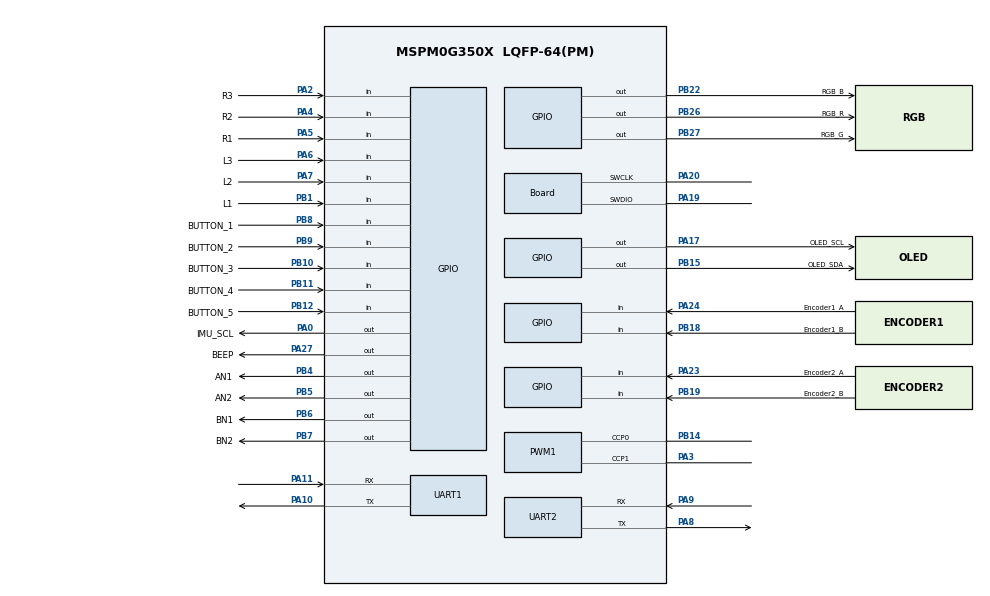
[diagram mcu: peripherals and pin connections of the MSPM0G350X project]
/**
 * @cliArgs --device "MSPM0G350X" --package "LQFP-64(PM)" --part "Default" --product "mspm0_sdk@2.00.01.00"
 * @versions {"tool":"1.20.0+3587"}
 */

/**
 * Import the modules used in this configuration.
 */
const ADC12         = scripting.addModule("/ti/driverlib/ADC12", {}, false);
const ADC121        = ADC12.addInstance();
const GPIO          = scripting.addModule("/ti/driverlib/GPIO", {}, false);
const GPIO1         = GPIO.addInstance();
const GPIO2         = GPIO.addInstance();
const GPIO3         = GPIO.addInstance();
const GPIO4         = GPIO.addInstance();
const PWM           = scripting.addModule("/ti/driverlib/PWM", {}, false);
const PWM1          = PWM.addInstance();
const SPI           = scripting.addModule("/ti/driverlib/SPI", {}, false);
const SPI1          = SPI.addInstance();
const SYSCTL        = scripting.addModule("/ti/driverlib/SYSCTL");
const SYSTICK       = scripting.addModule("/ti/driverlib/SYSTICK");
const TIMER         = scripting.addModule("/ti/driverlib/TIMER", {}, false);
const TIMER1        = TIMER.addInstance();
const TIMER2        = TIMER.addInstance();
const UART          = scripting.addModule("/ti/driverlib/UART", {}, false);
const UART1         = UART.addInstance();
const UART2         = UART.addInstance();
const ProjectConfig = scripting.addModule("/ti/project_config/ProjectConfig");

/**
 * Write custom configuration values to the imported modules.
 */
const divider2       = system.clockTree["HFCLK4MFPCLKDIV"];
divider2.divideValue = 10;

const divider6       = system.clockTree["PLL_CLK2X_DIV"];
divider6.divideValue = 4;

const divider7       = system.clockTree["PLL_PDIV"];
divider7.divideValue = 2;

const divider9       = system.clockTree["UDIV"];
divider9.divideValue = 2;

const multiplier2         = system.clockTree["PLL_QDIV"];
multiplier2.multiplyValue = 10;

const mux8       = system.clockTree["HSCLKMUX"];
mux8.inputSelect = "HSCLKMUX_SYSPLL2X";

const pinFunction4        = system.clockTree["HFXT"];
pinFunction4.inputFreq    = 40;
pinFunction4.HFXTStartup  = 20;
pinFunction4.HFCLKMonitor = true;

ADC121.$name               = "ADC12_0";
ADC121.sampClkSrc          = "DL_ADC12_CLOCK_ULPCLK";
ADC121.sampClkDiv          = "DL_ADC12_CLOCK_DIVIDE_8";
ADC121.powerDownMode       = "DL_ADC12_POWER_DOWN_MODE_MANUAL";
ADC121.sampleTime0         = "125us";
ADC121.adcMem0chansel      = "DL_ADC12_INPUT_CHAN_2";
ADC121.enabledInterrupts   = ["DL_ADC12_INTERRUPT_MEM0_RESULT_LOADED"];
ADC121.interruptPriority   = "3";
ADC121.adcPin2Config.$name = "ti_driverlib_gpio_GPIOPinGeneric6";

const Board                       = scripting.addModule("/ti/driverlib/Board", {}, false);
Board.peripheral.$assign          = "DEBUGSS";
Board.peripheral.swclkPin.$assign = "PA20";
Board.peripheral.swdioPin.$assign = "PA19";

GPIO1.$name                               = "PORTA";
GPIO1.port                                = "PORTA";
GPIO1.associatedPins.create(9);
GPIO1.associatedPins[0].$name             = "OLED_SCL";
GPIO1.associatedPins[0].internalResistor  = "PULL_UP";
GPIO1.associatedPins[0].pin.$assign       = "PA17";
GPIO1.associatedPins[1].$name             = "Encoder1_A";
GPIO1.associatedPins[1].direction         = "INPUT";
GPIO1.associatedPins[1].interruptEn       = true;
GPIO1.associatedPins[1].interruptPriority = "1";
GPIO1.associatedPins[1].polarity          = "RISE";
GPIO1.associatedPins[1].pin.$assign       = "PA24";
GPIO1.associatedPins[2].direction         = "INPUT";
GPIO1.associatedPins[2].$name             = "Encoder2_A";
GPIO1.associatedPins[2].interruptEn       = true;
GPIO1.associatedPins[2].interruptPriority = "1";
GPIO1.associatedPins[2].polarity          = "RISE";
GPIO1.associatedPins[2].pin.$assign       = "PA23";
GPIO1.associatedPins[3].$name             = "R2";
GPIO1.associatedPins[3].direction         = "INPUT";
GPIO1.associatedPins[3].pin.$assign       = "PA4";
GPIO1.associatedPins[4].$name             = "R3";
GPIO1.associatedPins[4].direction         = "INPUT";
GPIO1.associatedPins[4].pin.$assign       = "PA2";
GPIO1.associatedPins[5].$name             = "BEEP";
GPIO1.associatedPins[5].pin.$assign       = "PA27";
GPIO1.associatedPins[6].$name             = "L2";
GPIO1.associatedPins[6].direction         = "INPUT";
GPIO1.associatedPins[6].pin.$assign       = "PA7";
GPIO1.associatedPins[7].$name             = "L3";
GPIO1.associatedPins[7].direction         = "INPUT";
GPIO1.associatedPins[7].pin.$assign       = "PA6";
GPIO1.associatedPins[8].$name             = "R1";
GPIO1.associatedPins[8].direction         = "INPUT";
GPIO1.associatedPins[8].pin.$assign       = "PA5";

GPIO2.$name                               = "PORTB";
GPIO2.port                                = "PORTB";
GPIO2.associatedPins.create(11);
GPIO2.associatedPins[0].$name             = "RGB_R";
GPIO2.associatedPins[0].pin.$assign       = "PB26";
GPIO2.associatedPins[1].$name             = "RGB_G";
GPIO2.associatedPins[1].pin.$assign       = "PB27";
GPIO2.associatedPins[2].$name             = "RGB_B";
GPIO2.associatedPins[2].pin.$assign       = "PB22";
GPIO2.associatedPins[3].$name             = "OLED_SDA";
GPIO2.associatedPins[3].internalResistor  = "PULL_UP";
GPIO2.associatedPins[3].pin.$assign       = "PB15";
GPIO2.associatedPins[4].direction         = "INPUT";
GPIO2.associatedPins[4].interruptPriority = "1";
GPIO2.associatedPins[4].polarity          = "RISE";
GPIO2.associatedPins[4].$name             = "Encoder1_B";
GPIO2.associatedPins[4].pin.$assign       = "PB18";
GPIO2.associatedPins[5].$name             = "Encoder2_B";
GPIO2.associatedPins[5].direction         = "INPUT";
GPIO2.associatedPins[5].pin.$assign       = "PB19";
GPIO2.associatedPins[6].$name             = "AN1";
GPIO2.associatedPins[6].pin.$assign       = "PB4";
GPIO2.associatedPins[7].$name             = "AN2";
GPIO2.associatedPins[7].pin.$assign       = "PB5";
GPIO2.associatedPins[8].$name             = "BN1";
GPIO2.associatedPins[8].pin.$assign       = "PB6";
GPIO2.associatedPins[9].$name             = "BN2";
GPIO2.associatedPins[9].pin.$assign       = "PB7";
GPIO2.associatedPins[10].$name            = "L1";
GPIO2.associatedPins[10].direction        = "INPUT";
GPIO2.associatedPins[10].internalResistor = "PULL_UP";
GPIO2.associatedPins[10].pin.$assign      = "PB1";

GPIO3.port                               = "PORTB";
GPIO3.$name                              = "KEY";
GPIO3.associatedPins.create(5);
GPIO3.associatedPins[0].$name            = "BUTTON_1";
GPIO3.associatedPins[0].direction        = "INPUT";
GPIO3.associatedPins[0].internalResistor = "PULL_UP";
GPIO3.associatedPins[0].pin.$assign      = "PB8";
GPIO3.associatedPins[1].$name            = "BUTTON_2";
GPIO3.associatedPins[1].direction        = "INPUT";
GPIO3.associatedPins[1].internalResistor = "PULL_UP";
GPIO3.associatedPins[1].pin.$assign      = "PB9";
GPIO3.associatedPins[2].$name            = "BUTTON_3";
GPIO3.associatedPins[2].direction        = "INPUT";
GPIO3.associatedPins[2].internalResistor = "PULL_UP";
GPIO3.associatedPins[2].pin.$assign      = "PB10";
GPIO3.associatedPins[3].$name            = "BUTTON_4";
GPIO3.associatedPins[3].direction        = "INPUT";
GPIO3.associatedPins[3].internalResistor = "PULL_UP";
GPIO3.associatedPins[3].pin.$assign      = "PB11";
GPIO3.associatedPins[4].$name            = "BUTTON_5";
GPIO3.associatedPins[4].direction        = "INPUT";
GPIO3.associatedPins[4].internalResistor = "PULL_UP";
GPIO3.associatedPins[4].pin.$assign      = "PB12";

GPIO4.$name                          = "IMU";
GPIO4.port                           = "PORTA";
GPIO4.associatedPins.create(2);
GPIO4.associatedPins[0].$name        = "IMU_SDA";
GPIO4.associatedPins[0].ioStructure  = "OD";
GPIO4.associatedPins[0].initialValue = "SET";
GPIO4.associatedPins[1].$name        = "IMU_SCL";
GPIO4.associatedPins[1].ioStructure  = "OD";
GPIO4.associatedPins[1].initialValue = "SET";
GPIO4.associatedPins[1].pin.$assign  = "PA0";

PWM1.$name                      = "PWM_0";
PWM1.clockDivider               = 8;
PWM1.clockPrescale              = 10;
PWM1.pwmMode                    = "EDGE_ALIGN_UP";
PWM1.timerCount                 = 100;
PWM1.peripheral.ccp0Pin.$assign = "PB14";
PWM1.peripheral.ccp1Pin.$assign = "PA3";
PWM1.PWM_CHANNEL_0.$name        = "ti_driverlib_pwm_PWMTimerCC0";
PWM1.PWM_CHANNEL_1.$name        = "ti_driverlib_pwm_PWMTimerCC1";
PWM1.ccp0PinConfig.$name        = "ti_driverlib_gpio_GPIOPinGeneric4";
PWM1.ccp1PinConfig.$name        = "ti_driverlib_gpio_GPIOPinGeneric5";

SPI1.$name                              = "ICM_SPI_0";
SPI1.calculatedBitRate                  = -1;
SPI1.sclkPinConfig.direction            = scripting.forceWrite("OUTPUT");
SPI1.sclkPinConfig.onlyInternalResistor = scripting.forceWrite(false);
SPI1.sclkPinConfig.passedPeripheralType = scripting.forceWrite("Digital");
SPI1.sclkPinConfig.$name                = "ti_driverlib_gpio_GPIOPinGeneric9";
SPI1.mosiPinConfig.direction            = scripting.forceWrite("OUTPUT");
SPI1.mosiPinConfig.hideOutputInversion  = scripting.forceWrite(false);
SPI1.mosiPinConfig.onlyInternalResistor = scripting.forceWrite(false);
SPI1.mosiPinConfig.passedPeripheralType = scripting.forceWrite("Digital");
SPI1.mosiPinConfig.$name                = "ti_driverlib_gpio_GPIOPinGeneric10";
SPI1.misoPinConfig.onlyInternalResistor = scripting.forceWrite(false);
SPI1.misoPinConfig.passedPeripheralType = scripting.forceWrite("Digital");
SPI1.misoPinConfig.$name                = "ti_driverlib_gpio_GPIOPinGeneric11";
SPI1.cs0PinConfig.direction             = scripting.forceWrite("OUTPUT");
SPI1.cs0PinConfig.hideOutputInversion   = scripting.forceWrite(false);
SPI1.cs0PinConfig.onlyInternalResistor  = scripting.forceWrite(false);
SPI1.cs0PinConfig.passedPeripheralType  = scripting.forceWrite("Digital");
SPI1.cs0PinConfig.$name                 = "ti_driverlib_gpio_GPIOPinGeneric12";

SYSCTL.clockTreeEn = true;

SYSTICK.periodEnable      = true;
SYSTICK.period            = 80000;
SYSTICK.interruptEnable   = true;
SYSTICK.interruptPriority = "0";
SYSTICK.systickEnable     = true;

TIMER1.$name              = "TIMER_0";
TIMER1.timerMode          = "PERIODIC_UP";
TIMER1.interrupts         = ["ZERO"];
TIMER1.timerClkPrescale   = 5;
TIMER1.timerPeriod        = "5ms";
TIMER1.interruptPriority  = "2";
TIMER1.peripheral.$assign = "TIMG0";

TIMER2.timerClkDiv        = 8;
TIMER2.timerMode          = "PERIODIC_UP";
TIMER2.timerPeriod        = "1 ms";
TIMER2.interrupts         = ["ZERO"];
TIMER2.interruptPriority  = "1";
TIMER2.$name              = "TIMER_12";
TIMER2.peripheral.$assign = "TIMG12";

UART1.$name                    = "UART_0";
UART1.rxFifoThreshold          = "DL_UART_RX_FIFO_LEVEL_ONE_ENTRY";
UART1.enableDMARX              = false;
UART1.enableDMATX              = false;
UART1.enabledInterrupts        = ["RX"];
UART1.interruptPriority        = "1";
UART1.calculatedBaudRate       = -2;
UART1.peripheral.rxPin.$assign = "PA11";
UART1.peripheral.txPin.$assign = "PA10";
UART1.txPinConfig.$name        = "ti_driverlib_gpio_GPIOPinGeneric0";
UART1.rxPinConfig.$name        = "ti_driverlib_gpio_GPIOPinGeneric1";

UART2.$name                    = "UART_1";
UART2.enableFIFO               = true;
UART2.rxFifoThreshold          = "DL_UART_RX_FIFO_LEVEL_ONE_ENTRY";
UART2.enabledInterrupts        = ["RX"];
UART2.interruptPriority        = "1";
UART2.calculatedBaudRate       = -2;
UART2.peripheral.rxPin.$assign = "PA9";
UART2.peripheral.txPin.$assign = "PA8";
UART2.txPinConfig.$name        = "ti_driverlib_gpio_GPIOPinGeneric2";
UART2.rxPinConfig.$name        = "ti_driverlib_gpio_GPIOPinGeneric3";

ProjectConfig.deviceSpin = "MSPM0G3507";
scripting.suppress("Migrating requires going through the Switch Board or Device menu in the Device View section\\.", ProjectConfig, "deviceSpin");

/**
 * Pinmux solution for unlocked pins/peripherals. This ensures that minor changes to the automatic solver in a future
 * version of the tool will not impact the pinmux you originally saw.  These lines can be completely deleted in order to
 * re-solve from scratch.
 */
ADC121.peripheral.$suggestSolution           = "ADC0";
ADC121.peripheral.adcPin2.$suggestSolution   = "PA25";
GPIO4.associatedPins[0].pin.$suggestSolution = "PA1";
PWM1.peripheral.$suggestSolution             = "TIMA0";
SPI1.peripheral.$suggestSolution             = "SPI0";
SPI1.peripheral.sclkPin.$suggestSolution     = "PA12";
SPI1.peripheral.mosiPin.$suggestSolution     = "PA14";
SPI1.peripheral.misoPin.$suggestSolution     = "PA13";
SPI1.peripheral.cs0Pin.$suggestSolution      = "PB25";
UART1.peripheral.$suggestSolution            = "UART0";
UART2.peripheral.$suggestSolution            = "UART1";
